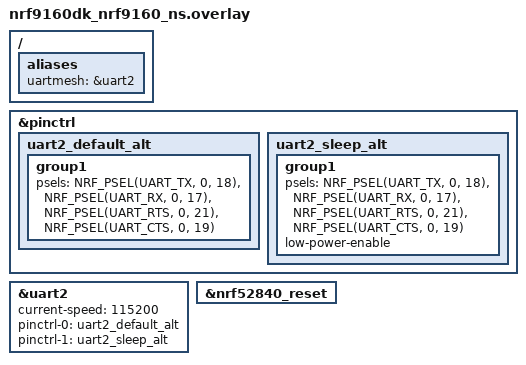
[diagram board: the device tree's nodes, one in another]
#include <nrf9160dk_nrf52840_reset_on_if5.dtsi>
/*
 * Copyright (c) 2021 Nordic Semiconductor ASA
 *
 * SPDX-License-Identifier: Apache-2.0
 */

 &pinctrl {
	uart2_default_alt: uart2_default_alt {
		group1 {
			psels = <NRF_PSEL(UART_TX, 0, 18)>,
				<NRF_PSEL(UART_RX, 0, 17)>,
				<NRF_PSEL(UART_RTS, 0, 21)>,
				<NRF_PSEL(UART_CTS, 0, 19)>;
		};
	};

	uart2_sleep_alt: uart2_sleep_alt {
		group1 {
			psels = <NRF_PSEL(UART_TX, 0, 18)>,
				<NRF_PSEL(UART_RX, 0, 17)>,
				<NRF_PSEL(UART_RTS, 0, 21)>,
				<NRF_PSEL(UART_CTS, 0, 19)>;
			low-power-enable;
		};
	};

};



&uart2 {
	status = "okay";
    current-speed = <115200>;
	pinctrl-0 = <&uart2_default_alt>;
	pinctrl-1 = <&uart2_sleep_alt>;
	pinctrl-names = "default", "sleep";
};


/{
    aliases{
        uartmesh=&uart2;
    };
};


&nrf52840_reset {
    status = "okay";
};
